AUTOSAR XML (schema 4-2-2)
standard types defined: uint8, uint16, uint32
package /AppPackage
  impl type dt_uint8: category=VALUE, base-type=uint8
  impl type dt_uint16: category=VALUE, base-type=uint16
  impl type dt_uint32: category=VALUE, base-type=uint32
  5 x sender receiver interface:
    IF_Pedal
      data Element_Throttle: type=dt_uint8
      data Element_Brake: type=dt_uint8
    IF_ButtonEvent
      data Element_Event: type=dt_uint8
      data Element_Seq: type=dt_uint8
    IF_VehicleSpeed
      data Element_Speed: type=dt_uint16
    IF_Distance
      data Element_Odo: type=dt_uint32
      data Element_Trip: type=dt_uint32
      data Element_NvStatus: type=dt_uint8
    IF_TripReset
      data Element_ReqSeq: type=dt_uint8
      data Element_OdoReqSeq: type=dt_uint8
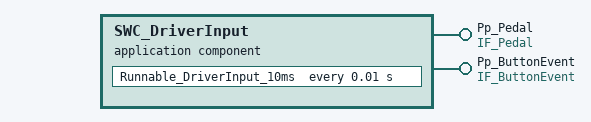
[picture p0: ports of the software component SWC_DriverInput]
  application sw component type SWC_DriverInput
    provide port Pp_Pedal: provided-interface=IF_Pedal
    provide port Pp_ButtonEvent: provided-interface=IF_ButtonEvent
    behavior IB_SWC_DriverInput
      timing event TE_DriverInput_10ms: start-on-event=Runnable_DriverInput_10ms, period=0.01
      runnable Runnable_DriverInput_10ms
        data-send-points:
          4 x access:
            DSP_Pedal_Throttle: accessed-variable=Pp_Pedal.Element_Throttle
            DSP_Pedal_Brake: accessed-variable=Pp_Pedal.Element_Brake
            DSP_ButtonEvent_Event: accessed-variable=Pp_ButtonEvent.Element_Event
            DSP_ButtonEvent_Seq: accessed-variable=Pp_ButtonEvent.Element_Seq
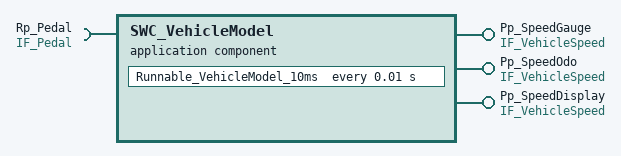
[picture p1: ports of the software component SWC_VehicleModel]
  application sw component type SWC_VehicleModel
    require port Rp_Pedal: required-interface=IF_Pedal
    provide port Pp_SpeedGauge: provided-interface=IF_VehicleSpeed
    provide port Pp_SpeedOdo: provided-interface=IF_VehicleSpeed
    provide port Pp_SpeedDisplay: provided-interface=IF_VehicleSpeed
    behavior IB_SWC_VehicleModel
      timing event TE_VehicleModel_10ms: start-on-event=Runnable_VehicleModel_10ms, period=0.01
      runnable Runnable_VehicleModel_10ms
        data-receive-point-by-arguments:
          access DRP_Pedal_Throttle: accessed-variable=Rp_Pedal.Element_Throttle
          access DRP_Pedal_Brake: accessed-variable=Rp_Pedal.Element_Brake
        data-send-points:
          access DSP_SpeedGauge_Speed: accessed-variable=Pp_SpeedGauge.Element_Speed
          access DSP_SpeedOdo_Speed: accessed-variable=Pp_SpeedOdo.Element_Speed
          access DSP_SpeedDisplay_Speed: accessed-variable=Pp_SpeedDisplay.Element_Speed
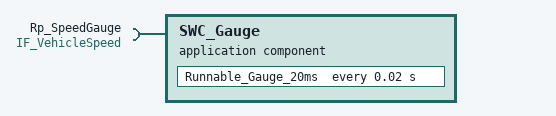
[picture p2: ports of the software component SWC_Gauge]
  application sw component type SWC_Gauge
    require port Rp_SpeedGauge: required-interface=IF_VehicleSpeed
    behavior IB_SWC_Gauge
      timing event TE_Gauge_20ms: start-on-event=Runnable_Gauge_20ms, period=0.02
      runnable Runnable_Gauge_20ms
        data-receive-point-by-arguments:
          access DRP_SpeedGauge_Speed: accessed-variable=Rp_SpeedGauge.Element_Speed
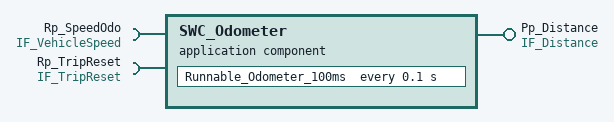
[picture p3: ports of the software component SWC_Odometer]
  application sw component type SWC_Odometer
    require port Rp_SpeedOdo: required-interface=IF_VehicleSpeed
    provide port Pp_Distance: provided-interface=IF_Distance
    require port Rp_TripReset: required-interface=IF_TripReset
    behavior IB_SWC_Odometer
      timing event TE_Odometer_100ms: start-on-event=Runnable_Odometer_100ms, period=0.1
      runnable Runnable_Odometer_100ms
        data-receive-point-by-arguments:
          access DRP_SpeedOdo_Speed: accessed-variable=Rp_SpeedOdo.Element_Speed
          access DRP_TripReset_ReqSeq: accessed-variable=Rp_TripReset.Element_ReqSeq
          access DRP_TripReset_OdoReqSeq: accessed-variable=Rp_TripReset.Element_OdoReqSeq
        data-send-points:
          access DSP_Distance_Odo: accessed-variable=Pp_Distance.Element_Odo
          access DSP_Distance_Trip: accessed-variable=Pp_Distance.Element_Trip
          access DSP_Distance_NvStatus: accessed-variable=Pp_Distance.Element_NvStatus
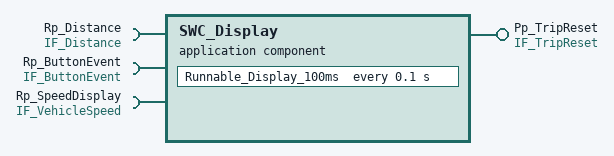
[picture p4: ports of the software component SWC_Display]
  application sw component type SWC_Display
    require port Rp_Distance: required-interface=IF_Distance
    require port Rp_ButtonEvent: required-interface=IF_ButtonEvent
    provide port Pp_TripReset: provided-interface=IF_TripReset
    require port Rp_SpeedDisplay: required-interface=IF_VehicleSpeed
    behavior IB_SWC_Display
      timing event TE_Display_100ms: start-on-event=Runnable_Display_100ms, period=0.1
      runnable Runnable_Display_100ms
        data-receive-point-by-arguments:
          6 x access:
            DRP_Distance_Odo: accessed-variable=Rp_Distance.Element_Odo
            DRP_Distance_Trip: accessed-variable=Rp_Distance.Element_Trip
            DRP_Distance_NvStatus: accessed-variable=Rp_Distance.Element_NvStatus
            DRP_ButtonEvent_Event: accessed-variable=Rp_ButtonEvent.Element_Event
            DRP_ButtonEvent_Seq: accessed-variable=Rp_ButtonEvent.Element_Seq
            DRP_SpeedDisplay_Speed: accessed-variable=Rp_SpeedDisplay.Element_Speed
        data-send-points:
          access DSP_TripReset_ReqSeq: accessed-variable=Pp_TripReset.Element_ReqSeq
          access DSP_TripReset_OdoReqSeq: accessed-variable=Pp_TripReset.Element_OdoReqSeq
  composition sw component type Cluster_Composition
    5 x component:
      CP_DriverInput: type=SWC_DriverInput
      CP_VehicleModel: type=SWC_VehicleModel
      CP_Gauge: type=SWC_Gauge
      CP_Odometer: type=SWC_Odometer
      CP_Display: type=SWC_Display
    connect CP_DriverInput.Pp_Pedal -> CP_VehicleModel.Rp_Pedal
    connect CP_DriverInput.Pp_ButtonEvent -> CP_Display.Rp_ButtonEvent
    connect CP_VehicleModel.Pp_SpeedGauge -> CP_Gauge.Rp_SpeedGauge
    connect CP_VehicleModel.Pp_SpeedOdo -> CP_Odometer.Rp_SpeedOdo
    connect CP_VehicleModel.Pp_SpeedDisplay -> CP_Display.Rp_SpeedDisplay
    connect CP_Odometer.Pp_Distance -> CP_Display.Rp_Distance
    connect CP_Display.Pp_TripReset -> CP_Odometer.Rp_TripReset
